# M031AE_v1 register map
File version: 1.0
Registers are 32-bit, read-write, reset 0x0 unless marked. A register's access mark holds for its fields unless they carry their own. Offsets are from the block's base; [hi:lo] are bit positions; {n}, {i} and the like mark numbered series.

## FMC — FMC Register Map
Base 0x4000C000
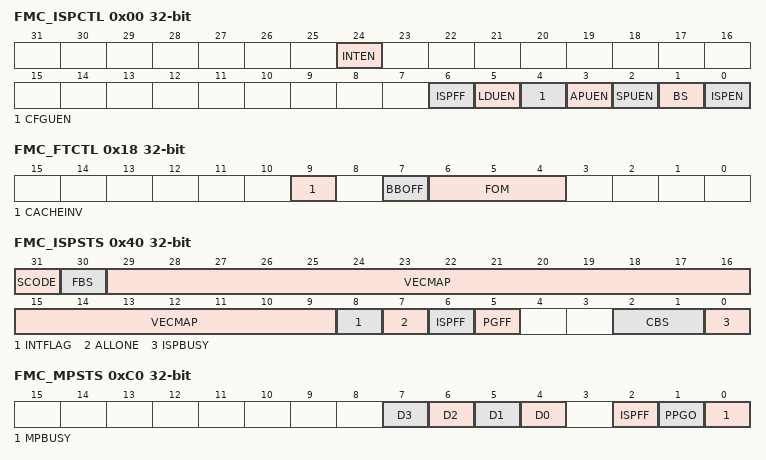
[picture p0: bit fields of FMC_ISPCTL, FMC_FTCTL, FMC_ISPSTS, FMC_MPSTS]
0x00 FMC_ISPCTL (reset mask 0xFFFFFFF0) — ISP Control Register
  [24] INTEN — ISP Interrupt Enabled Bit (Write Protect). Note: This bit is write protected. Refer to the SYS_REGLCTL register.Before use INT,user needs to clear the INTFLAG(FMC_ISPSTS[8]) make sure INT happen at correct time.
    0=ISP INT Disabled; 1=ISP INT Enabled
  [6] ISPFF — ISP Fail Flag (Write Protect). This bit is set by hardware when a triggered ISP meets any of the following conditions: This bit needs to be cleared by writing 1 to it. APROM writes to itself if APUEN is set to 0. LDROM writes to itself if LDUEN is set to 0. CONFIG is erased/programmed if CFGUEN is set to 0. SPROM is erased/programmed if SPUEN is set to 0. SPROM is programmed at SPROM secured mode. Page Erase command at LOCK mode with ICE connection. Erase or Program command at brown-out detected. Destination address is illegal, such as over an available range. Invalid ISP commands. Note: This bit is write-protected. Refer to the SYS_REGLCTL register.
  [5] LDUEN — LDROM Update Enable Bit (Write Protect). LDROM update enable bit. Note: This bit is write-protected. Refer to the SYS_REGLCTL register.
    0=LDROM cannot be updated; 1=LDROM can be updated
  [4] CFGUEN — CONFIG Update Enable Bit (Write Protect). Note: This bit is write-protected. Refer to the SYS_REGLCTL register.
    0=CONFIG cannot be updated; 1=CONFIG can be updated
  [3] APUEN — APROM Update Enable Bit (Write Protect). Note: This bit is write-protected. Refer to the SYS_REGLCTL register.
    0=APROM cannot be updated when the chip runs in APROM; 1=APROM can be updated when the chip runs in APROM
  [2] SPUEN — SPROM Update Enable Bit (Write Protect). Note: This bit is write-protected. Refer to the SYS_REGLCTL register.
    0=SPROM cannot be updated; 1=SPROM can be updated
  [1] BS — Boot Selection (Write Protect). Set/clear this bit to select next booting from LDROM/APROM, respectively. This bit also functions as chip booting status flag, which can be used to check where chip booted from. This bit is initiated with the inversed value of CBS[1] (CONFIG0[7]) after any reset is happened except CPU reset (RSTS_CPU is 1) or system reset (RSTS_SYS) is happened. Note: This bit is write-protected. Refer to the SYS_REGLCTL register.
    0=Booting from APROM; 1=Booting from LDROM
  [0] ISPEN — ISP Enable Bit (Write Protect). Note: This bit is write-protected. Refer to the SYS_REGLCTL register.
    1=ISP function Enabled
0x04 FMC_ISPADDR — ISP Address Register
  [31:0] ISPADDR — ISP Address. The M031/M032 series is equipped with embedded Flash. ISPADDR[1:0] must be kept 00 for ISP 32-bit operation. For CRC32 Checksum Calculation command, this field is the Flash starting address for checksum calculation, 512 bytes alignment is necessary for checksum calculation. 16/32/64/128 Kbytes Flash: ISPADR[8:0] must be kept all 0 for Vector Page Re-map Command. 256/512 Kbytes Flash: ISPADR[11:0] must be kept all 0 for Vector Page Re-map Command.
0x08 FMC_ISPDAT — ISP Data Register
  [31:0] ISPDAT — ISP Data. Write data to this register before ISP program operation. Read data from this register after ISP read operation.
0x0C FMC_ISPCMD — ISP Command Register
  [6:0] CMD — ISP CMD. ISP command table is shown below: The other commands are invalid.
    0=Flash Read; 4=Read Unique ID; 8=Read All One; 11=Read Company ID; 12=Read Device ID; 13=Read CRC32 Checksum; 33=Flash 32-bit Program; 34=Flash Page Erase; 35=Flash APROM Bank Erase; 39=Flash Multi-Word Program; 40=Run All One; 44=APROM Address Operation Model Selection; 45=Run CRC32 Checksum Calculation; 46=Vector Remap; 97=Flash 64-bit Program
0x10 FMC_ISPTRG — ISP Trigger Control Register
  [0] ISPGO — ISP Start Trigger (Write Protect). Write 1 to start ISP operation and this bit will be cleared to 0 by hardware automatically when ISP operation is finished.
    0=ISP operation is finished; 1=ISP is progressed.Note: This bit is write-protected. Refer to the SYS_REGLCTL register
0x14 FMC_DFBA ro reset not defined — Data Flash Base Address
  [31:0] DFBA — Data Flash Base Address. This register indicates Data Flash start address. It is a read only register. The Data Flash is shared with APROM. the content of this register is loaded from CONFIG1
0x18 FMC_FTCTL — Flash Access Time Control Register
  [9] CACHEINV — Flash Cache Invalidation (Write Protect). Note 1: Write 1 to start cache invalidation. The value will be changed to 0 once the process is finished. Note 2: This bit is write-protected. Refer to the SYS_REGLCTL register. Note 3: Only supported in 256/512 Kbytes Flash.
    0=Flash Cache Invalidation finished (default); 1=Flash Cache Invalidation
  [7] BBOFF — Flash Branch Buffer Disable Control (Write Protect). Note 1: This bit is write-protected. Refer to the SYS_REGLCTL register. Note 2: Only suppoted in 16/32/64/128 Kbytes Flash.
    0=Flash Branch Buffer function Enabled (default); 1=Flash Branch Buffer function Disabled
  [6:4] FOM — Frequency Optimization Mode (Write Protect). The M031/M032 series support adjustable Flash access timing to optimize the Flash access cycles in different system working frequency. For 16/32/64/128 Kbytes Flash: Note: This bit is write-protected. Refer to the SYS_REGLCTL register.
    0=Frequency is less than or equal to 48 MHz; 1=Frequency is less than or equal to 24 MHz. Frequency is less than or equal to 12 MHz; 2=Frequency is less than or equal to 36 MHz; 3=Frequency is less than or equal to 60 MHz
0x40 FMC_ISPSTS (reset mask 0xF0FFFF0) — ISP Status Register
  [31] SCODE — Security Code Active Flag. This bit is set to 1 by hardware when detecting SPROM secured code is active at Flash initialization, or software writes 1 to this bit to make secured code active; this bit is only cleared by SPROM page erase operation.
    0=SPROM secured code is inactive; 1=SPROM secured code is active
  [30] FBS — Flash Bank Select Indicator. This bit indicates which APROM address model is selected to boot. Note: Only supported in 256/512 Kbytes Flash.
    0=Address model OP0 is selected to boot; 1=Address model OP1 is selected to boot
  [29:9] VECMAP ro — Vector Page Mapping Address (Read Only). All access to 0x0000_0000~0x0000_01FF is remapped to the Flash memory or SRAM address {VECMAP[20:0], 9'h000} ~ {VECMAP[20:0], 9'h1FF}, except SPROM. VECMAP [18:12] should be 0.
  [8] INTFLAG — ISP Command Finish Interrupt Flag. Note: Only supported in 256/512 Kbytes Flash.
    0=ISP Not Finished; 1=ISP done or ISPFF set
  [7] ALLONE — Flash All-one Verification Flag. This bit is set by hardware if all of Flash bits are 1, and cleared if Flash bits are not all 1 after 'Run Flash All-One Verification' complete; this bit can also be cleared by writing 1.
    0=Flash bits are not all 1 after'Run Flash All-One Verification' complete; 1=All of Flash bits are 1 after'Run Flash All-One Verification' complete
  [6] ISPFF — ISP Fail Flag (Write Protect). This bit is the mirror of ISPFF (FMC_ISPCTL[6]), it needs to be cleared by writing 1 to FMC_ISPCTL[6] or FMC_ISPSTS[6]. This bit is set by hardware when a triggered ISP meets any of the following conditions: APROM writes to itself if APUEN is set to 0. LDROM writes to itself if LDUEN is set to 0. CONFIG is erased/programmed if CFGUEN is set to 0. SPROM is erased/programmed if SPUEN is set to 0. SPROM is programmed at SPROM secured mode. Page Erase command at LOCK mode with ICE connection. Erase or Program command at brown-out detected. Destination address is illegal, such as over an available range. Invalid ISP commands
  [5] PGFF ro — Flash Program with Fast Verification Flag (Read Only). This bit is set if data is mismatched at ISP programming verification. This bit is clear by performing ISP Flash erase or ISP read CID operation
    0=Flash Program is successful; 1=Flash Program is failed. Program data is different with data in the Flash memory
  [2:1] CBS ro — Boot Selection of CONFIG (Read Only). This bit is initiated with the CBS (CONFIG0[7:6]) after any reset is happened except CPU reset (RSTS_CPU is 1) or system reset (RSTS_SYS) is happened.
    0=LDROM with IAP mode; 1=LDROM without IAP mode; 2=APROM with IAP mode; 3=APROM without IAP mode
  [0] ISPBUSY ro — ISP BUSY (Read Only)
    0=ISP operation is finished; 1=ISP operation is busy
0x80 FMC_MPDAT0 — ISP Data0 Register
  [31:0] ISPDAT0 — ISP Data 0. This register is the first 32-bit data for 32-bit/64-bit/multi-word programming, and it is also the mirror of FMC_ISPDAT, both registers keep the same data.
0x84 FMC_MPDAT1 — ISP Data1 Register
  [31:0] ISPDAT1 — ISP Data 1. This register is the second 32-bit data for 64-bit/multi-word programming.
0x88 FMC_MPDAT2 — ISP Data2 Register
  [31:0] ISPDAT2 — ISP Data 2. This register is the third 32-bit data for multi-word programming.
0x8C FMC_MPDAT3 — ISP Data3 Register
  [31:0] ISPDAT3 — ISP Data 3. This register is the fourth 32-bit data for multi-word programming.
0xC0 FMC_MPSTS ro — ISP Multi-program Status Register
  [n+4] D{n} (n=0..3) — ISP DATA {n} Flag (Read Only). This bit is set when FMC_MPDAT{n} is written and auto cleared to 0 when the FMC_MPDAT{n} data is programmed to Flash complete.
    0=FMC_MPDAT{n} register is empty, or program to Flash complete; 1=FMC_MPDAT{n} register has been written, and not program to Flash complete
  [2] ISPFF — ISP Fail Flag (Read Only). This bit is the mirror of ISPFF (FMC_ISPCTL[6]), it needs to be cleared by writing 1 to FMC_ISPCTL[6] or FMC_ISPSTS[6]. This bit is set by hardware when a triggered ISP meets any of the following conditions: APROM writes to itself if APUEN is set to 0. LDROM writes to itself if LDUEN is set to 0. CONFIG is erased/programmed if CFGUEN is set to 0. Page Erase command at LOCK mode with ICE connection. Erase or Program command at brown-out detected. Destination address is illegal, such as over an available range. Invalid ISP commands
  [1] PPGO — ISP Multi-program Status (Read Only)
    0=ISP multi-word program operation is not active; 1=ISP multi-word program operation is in progress
  [0] MPBUSY — ISP Multi-word Program Busy Flag (Read Only). Write 1 to start ISP Multi-Word program operation and this bit will be cleared to 0 by hardware automatically when ISP Multi-Word program operation is finished. This bit is the mirror of ISPGO(FMC_ISPTRG[0]).
    0=ISP Multi-Word program operation is finished; 1=ISP Multi-Word program operation is progressed
0xC4 FMC_MPADDR ro — ISP Multi-program Address Register
  [31:0] MPADDR — ISP Multi-word Program Address. MPADDR is the address of ISP multi-word program operation when ISPGO flag is 1. MPADDR will keep the final ISP address when ISP multi-word program is complete.
